# STM32L151xCA register map
File version: 1.0
Registers are 32-bit, read-write, reset 0x0 unless marked. A register's access mark holds for its fields unless they carry their own. Offsets are from the block's base; [hi:lo] are bit positions; {n}, {i} and the like mark numbered series.

## OB — Option Bytes Registers
Base 0x1FF80000
0x00 RDP — Read protection register
0x04 USER
0x08 WRP01 — write protection register 0 1
0x0C WRP23 — write protection register 2 3
0x10 WRP45 — write protection register 4 5
0x14 WRP67 — write protection register 6 7

## TIM6 — TIM
Base 0x40001000
Same registers: TIM7 0x40001400
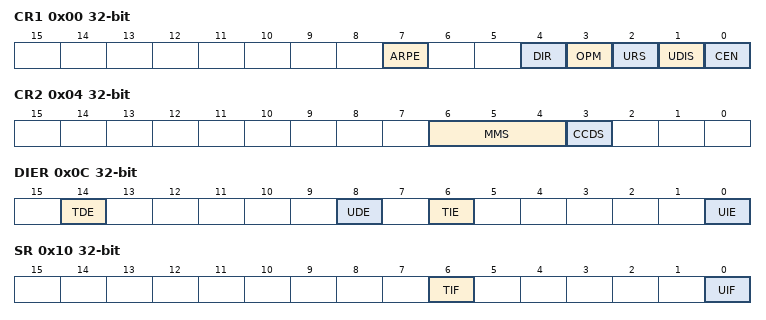
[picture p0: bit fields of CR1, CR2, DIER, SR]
0x00 CR1 — TIM control register 1
  [7] ARPE — Auto-reload preload enable
  [4] DIR — Direction
    0=UP (Timer counter counts up); 1=DOWN (Timer counter counts down)
  [3] OPM — One pulse mode
    1=SINGLE (Counter stops counting at the next update event); 0=REPETITIVE (Counter is not stopped at update event)
  [2] URS — Update request source
    0=REGULAR (Counter overflow/underflow, Setting the UG bit or Update generation through the slave mode controller generates an update request); 1=COUNTER (Only counter overflow/underflow generates an update request)
  [1] UDIS — Update disable
  [0] CEN — Counter enable
0x04 CR2 — TIM control register 2
  [6:4] MMS — MMS[2:0] bits (Master Mode Selection)
    0=RESET (UG bit from the TIMx_EGR register is used as trigger output); 1=ENABLE (Counter Enable signal (CNT_EN) is used as trigger output); 2=UPDATE (Update event is used as trigger output); 3=CC1IF (CC1 capture or a compare match is used as trigger output); {v}=OC{v-3}REF (OC{v-3}REF signal is used as trigger output) (v=4..7)
  [3] CCDS — Capture/Compare DMA Selection
    0=CC (CCx DMA request sent when CCx event occurs); 1=UPDATE (CCx DMA requests sent when update event occurs)
0x08 SMCR — TIM slave Mode Control register
  [3] OCCS — OCREF clear selection
    0=OCREF_CLR (OCREF_CLR_INT is connected to the OCREF_CLR input); 1=ETR (OCREF_CLR_INT is connected to ETRF)
0x0C DIER — TIM DMA/interrupt enable register
  [14] TDE — Trigger DMA request enable
  [8] UDE — Update DMA request enable
  [6] TIE — Trigger interrupt enable
  [0] UIE — Update interrupt enable
0x10 SR — TIM status register
  [6] TIF — Trigger interrupt Flag
  [0] UIF — Update interrupt Flag
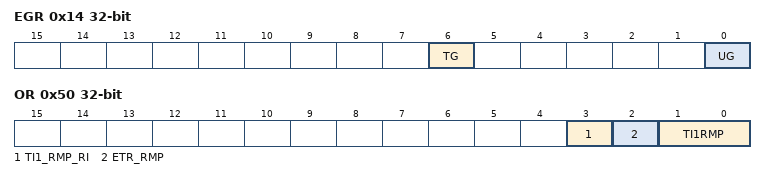
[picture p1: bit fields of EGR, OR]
0x14 EGR — TIM event generation register
  [6] TG — Trigger Generation
  [0] UG — Update Generation
0x24 CNT — TIM counter register
  [15:0] CNT — Counter Value
0x28 PSC — TIM prescaler register
  [15:0] PSC — Prescaler Value
0x2C ARR — TIM auto-reload register
  [15:0] ARR — actual auto-reload Value
0x4C DMAR — TIM DMA address for full transfer
  [15:0] DMAB — DMA register for burst accesses
0x50 OR — TIM option register
  [3] TI1_RMP_RI — TI1_RMP_RI bit (TIM10/11 Input 1 remap for Routing interface)
  [2] ETR_RMP — ETR_RMP bit (TIM10/11 ETR remap)
  [1:0] TI1RMP — TI1_RMP[1:0] bits (TIM Input 1 remap)

## WWDG — Window WATCHDOG
Base 0x40002C00
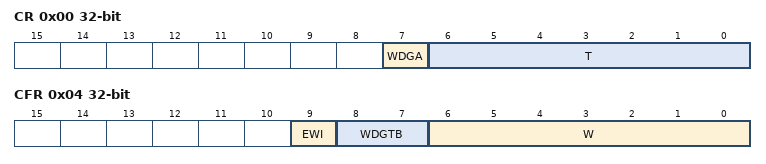
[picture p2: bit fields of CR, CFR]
0x00 CR — WWDG Control register
  [7] WDGA — Activation bit
  [6:0] T — T[6:0] bits (7-Bit counter (MSB to LSB))
0x04 CFR — WWDG Configuration register
  [9] EWI — Early Wakeup Interrupt
  [8:7] WDGTB — WDGTB[1:0] bits (Timer Base)
    0=PRESCALER_1 (WWDG counter clock = (PCLK1/4096)/1); 1=PRESCALER_2 (WWDG counter clock = (PCLK1/4096)/2); 2=PRESCALER_4 (WWDG counter clock = (PCLK1/4096)/4); 3=PRESCALER_8 (WWDG counter clock = (PCLK1/4096)/8)
  [6:0] W — W[6:0] bits (7-bit window value)
0x08 SR — WWDG Status register
  [0] EWIF — Early Wakeup Interrupt Flag

## IWDG — Independent WATCHDOG
Base 0x40003000
0x00 KR — Key register
  [15:0] KEY — Key value (write only, read 0000h)
0x04 PR — Prescaler register
  [2:0] PR — PR[2:0] (Prescaler divider)
0x08 RLR — Reload register
  [11:0] RL — Watchdog counter reload value
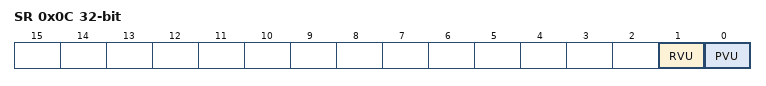
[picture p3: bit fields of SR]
0x0C SR — Status register
  [1] RVU — Watchdog counter reload value update
  [0] PVU — Watchdog prescaler value update

## SPI2 — Serial Peripheral Interface
Base 0x40003800
Same registers: SPI3 0x40003C00, SPI1 0x40013000
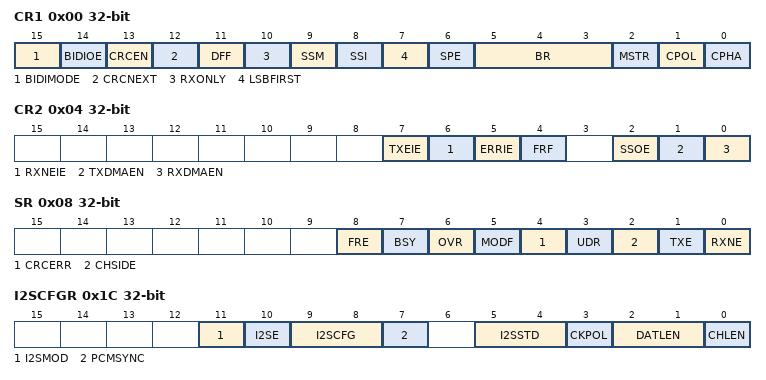
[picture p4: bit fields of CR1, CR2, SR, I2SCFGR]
0x00 CR1 — SPI Control register 1 (not used in I2S mode)
  [15] BIDIMODE — Bidirectional data mode enable
  [14] BIDIOE — Output enable in bidirectional mode
  [13] CRCEN — Hardware CRC calculation enable
  [12] CRCNEXT — Transmit CRC next
  [11] DFF — Data Frame Format
    0=DATAWIDTH_8BIT (Data length for SPI transfer: 8 bits); 1=DATAWIDTH_16BIT (Data length for SPI transfer: 16 bits)
  [10] RXONLY — Receive only
  [9] SSM — Software slave management
  [8] SSI — Internal slave select
  [7] LSBFIRST — Frame Format
    1=LSB_FIRST (Data is transmitted/received with the LSB first); 0=MSB_FIRST (Data is transmitted/received with the MSB first)
  [6] SPE — SPI Enable
  [5:3] BR — BR[2:0] bits (Baud Rate Control)
    0=DIV2 (BaudRate control equal to fPCLK/2); 1=DIV4 (BaudRate control equal to fPCLK/4); 2=DIV8 (BaudRate control equal to fPCLK/8); 3=DIV16 (BaudRate control equal to fPCLK/16); 4=DIV32 (BaudRate control equal to fPCLK/32); 5=DIV64 (BaudRate control equal to fPCLK/64); 6=DIV128 (BaudRate control equal to fPCLK/128); 7=DIV256 (BaudRate control equal to fPCLK/256)
  [2] MSTR — Master Selection
  [1] CPOL — Clock Polarity
    0=LOW (Clock to 0 when idle); 1=HIGH (Clock to 1 when idle)
  [0] CPHA — Clock Phase
    0=PHASE_1EDGE (First clock transition is the first data capture edge); 1=PHASE_2EDGE (Second clock transition is the first data capture edge)
0x04 CR2 — SPI Control register 2
  [7] TXEIE — Tx buffer Empty Interrupt Enable
  [6] RXNEIE — RX buffer Not Empty Interrupt Enable
  [5] ERRIE — Error Interrupt Enable
  [4] FRF — Frame format
    0=MOTOROLA (Motorola mode. Used as default value); 1=TI (TI mode)
  [2] SSOE — SS Output Enable
  [1] TXDMAEN — Tx Buffer DMA Enable
  [0] RXDMAEN — Rx Buffer DMA Enable
0x08 SR — SPI Status register
  [8] FRE — Frame format error flag
  [7] BSY — Busy flag
  [6] OVR — Overrun flag
  [5] MODF — Mode fault
  [4] CRCERR — CRC Error flag
  [3] UDR — Underrun flag
  [2] CHSIDE — Channel side
  [1] TXE — Transmit buffer Empty
  [0] RXNE — Receive buffer Not Empty
0x0C DR — SPI data register
  [15:0] DR — Data Register
0x10 CRCPR — SPI CRC polynomial register (not used in I2S mode)
  [15:0] CRCPOLY — CRC polynomial register
0x14 RXCRCR — SPI Rx CRC register (not used in I2S mode)
  [15:0] RXCRC
0x18 TXCRCR — SPI Tx CRC register (not used in I2S mode)
  [15:0] TXCRC
0x1C I2SCFGR — SPI_I2S configuration register
  [11] I2SMOD — I2S mode selection
  [10] I2SE — I2S Enable
  [9:8] I2SCFG — I2SCFG[1:0] bits (I2S configuration mode)
    0=SLAVE_TX (Slave Tx configuration); 1=SLAVE_RX (Slave Rx configuration); 2=MASTER_TX (Master Tx configuration); 3=MASTER_RX (Master Rx configuration)
  [7] PCMSYNC — PCM frame synchronization
  [5:4] I2SSTD — I2SSTD[1:0] bits (I2S standard selection)
  [3] CKPOL — steady state clock polarity
    0=LOW (Clock steady state is low level); 1=HIGH (Clock steady state is high level)
  [2:1] DATLEN — DATLEN[1:0] bits (Data length to be transferred)
  [0] CHLEN — Channel length (number of bits per audio channel)
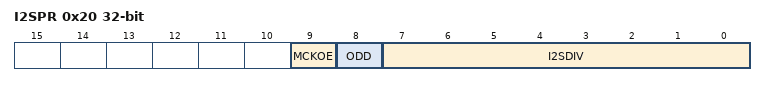
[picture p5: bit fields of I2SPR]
0x20 I2SPR — SPI_I2S prescaler register
  [9] MCKOE — Master Clock Output Enable
  [8] ODD — Odd factor for the prescaler
  [7:0] I2SDIV — I2S Linear prescaler
